# N32H7xx register map
Vendor: Nationstech Ltd.; File version: 1.0
Registers are 32-bit, read-write, reset 0x0 unless marked. A register's access mark holds for its fields unless they carry their own. Offsets are from the block's base; [hi:lo] are bit positions; {n}, {i} and the like mark numbered series; 'fields as' and 'values as' point back to an identical list.

## DMAMUX1 — DMA request multiplexer
Base 0x40046400
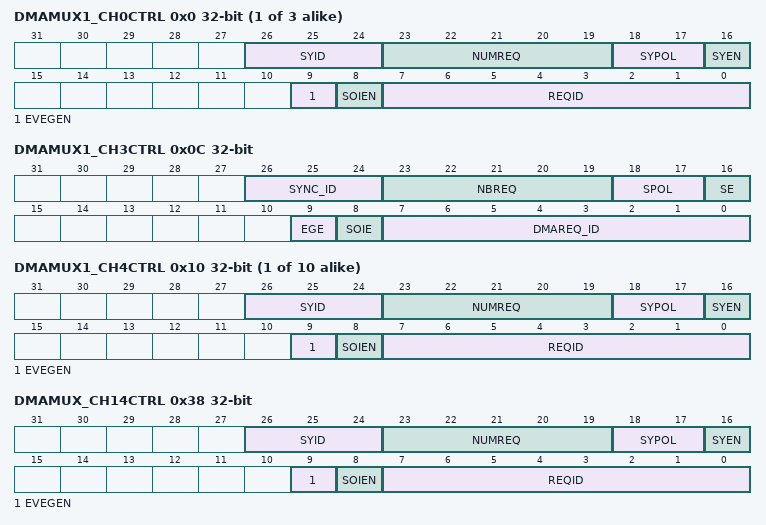
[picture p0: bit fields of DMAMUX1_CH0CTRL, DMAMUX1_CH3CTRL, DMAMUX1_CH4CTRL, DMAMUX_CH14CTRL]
{0x0+4i} DMAMUX1_CH{i}CTRL (i=0..2) — nan
  [26:24] SYID, [23:19] NUMREQ, [18:17] SYPOL, [16] SYEN, [9] EVEGEN, [8] SOIEN, [7:0] REQID
0x0C DMAMUX1_CH3CTRL — nan
  [26:24] SYNC_ID, [23:19] NBREQ, [18:17] SPOL, [16] SE, [9] EGE, [8] SOIE, [7:0] DMAREQ_ID
{0x0+4i} DMAMUX1_CH{i}CTRL (i=4..13) — nan
  fields as DMAMUX1_CH0CTRL
0x38 DMAMUX_CH14CTRL — nan
  fields as DMAMUX1_CH0CTRL
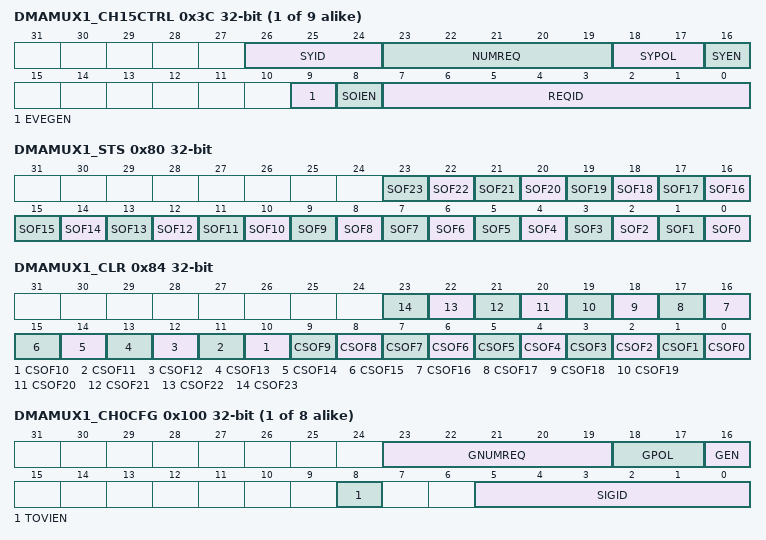
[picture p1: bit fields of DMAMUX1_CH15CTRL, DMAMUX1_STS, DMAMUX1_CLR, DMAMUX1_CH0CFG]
{0x0+4i} DMAMUX1_CH{i}CTRL (i=15..23) — nan
  fields as DMAMUX1_CH0CTRL
0x80 DMAMUX1_STS ro — nan
  [n] SOF{n} (n=0..23)
0x84 DMAMUX1_CLR — nan
  [n] CSOF{n} (n=0..23)
{0x100+4i} DMAMUX1_CH{i}CFG (i=0..7) — nan
  [23:19] GNUMREQ, [18:17] GPOL, [16] GEN, [8] TOVIEN, [5:0] SIGID
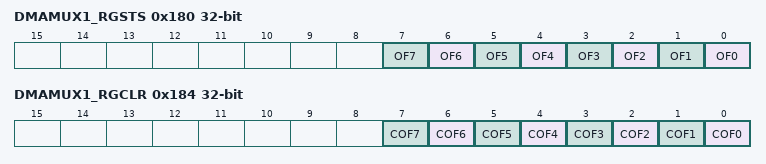
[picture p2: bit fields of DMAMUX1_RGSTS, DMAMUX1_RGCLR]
0x180 DMAMUX1_RGSTS ro — nan
  [n] OF{n} (n=0..7)
0x184 DMAMUX1_RGCLR — nan
  [n] COF{n} (n=0..7)

## DMAMUX2 — DMA request multiplexer
Base 0x51120000
Registers as DMAMUX1 (with DMAMUX1 read as DMAMUX2), without DMAMUX_CH14CTRL, DMAMUX1_CH{n}CTRL (n=16..23); these are added or differ:
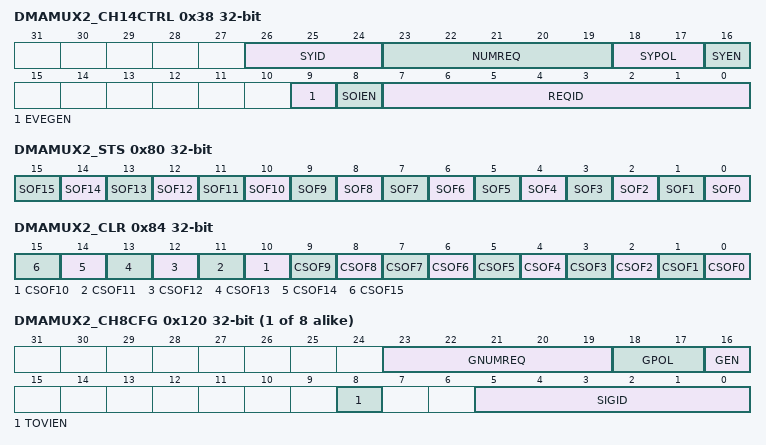
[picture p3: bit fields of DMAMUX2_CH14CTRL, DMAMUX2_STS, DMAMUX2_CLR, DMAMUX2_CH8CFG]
0x38 DMAMUX2_CH14CTRL — nan
  [26:24] SYID, [23:19] NUMREQ, [18:17] SYPOL, [16] SYEN, [9] EVEGEN, [8] SOIEN, [7:0] REQID
0x80 DMAMUX2_STS ro — nan
  [n] SOF{n} (n=0..15)
0x84 DMAMUX2_CLR — nan
  [n] CSOF{n} (n=0..15)
{0x100+4i} DMAMUX2_CH{i}CFG (i=8..15) — nan
  [23:19] GNUMREQ, [18:17] GPOL, [16] GEN, [8] TOVIEN, [5:0] SIGID
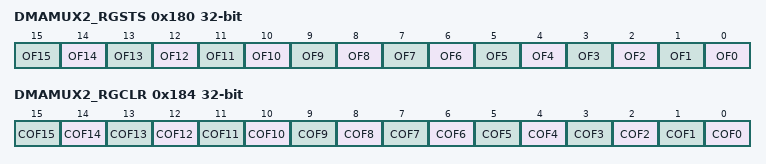
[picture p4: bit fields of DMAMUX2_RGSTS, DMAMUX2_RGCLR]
0x180 DMAMUX2_RGSTS ro — nan
  [n] OF{n} (n=0..15)
0x184 DMAMUX2_RGCLR — nan
  [n] COF{n} (n=0..15)

## DMA1 — DMA controller 1
Base 0x40046800
Same registers: DMA2 0x40046C00, DMA3 0x40047000
{0x0+0x58*i} DMA_CH{i}SA (i=0..7)
  [31:0] ADDR
{0x8+0x58*i} DMA_CH{i}DA (i=0..7)
  [31:0] ADDR
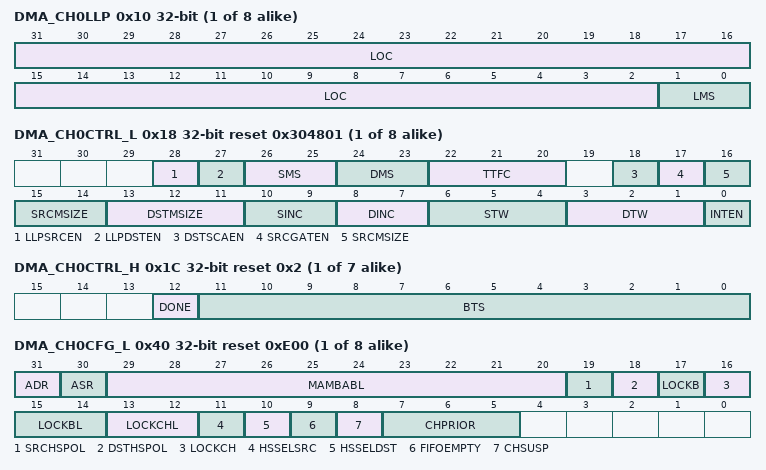
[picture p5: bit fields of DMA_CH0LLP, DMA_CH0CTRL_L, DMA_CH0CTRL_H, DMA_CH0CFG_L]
{0x10+0x58*i} DMA_CH{i}LLP (i=0..7)
  [31:2] LOC, [1:0] LMS
{0x18+0x58*i} DMA_CH{i}CTRL_L reset 0x304801 (i=0..7)
  [28] LLPSRCEN, [27] LLPDSTEN, [26:25] SMS, [24:23] DMS, [22:20] TTFC, [18] DSTSCAEN, [17] SRCGATEN, [16:14] SRCMSIZE, [13:11] DSTMSIZE, [10:9] SINC, [8:7] DINC, [6:4] STW, [3:1] DTW, [0] INTEN
{0x1C+0x58*i} DMA_CH{i}CTRL_H reset 0x2 (i=0..6)
  [12] DONE, [11:0] BTS
{0x40+0x58*i} DMA_CH{i}CFG_L reset 0xE00 (i=0..7)
  [31] ADR, [30] ASR, [29:20] MAMBABL, [19] SRCHSPOL, [18] DSTHSPOL, [17] LOCKB, [16] LOCKCH, [15:14] LOCKBL, [13:12] LOCKCHL, [11] HSSELSRC, [10] HSSELDST, [9] FIFOEMPTY, [8] CHSUSP, [7:5] CHPRIOR
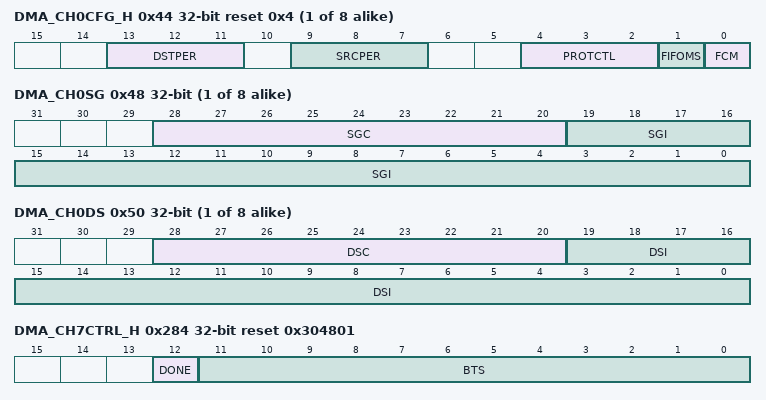
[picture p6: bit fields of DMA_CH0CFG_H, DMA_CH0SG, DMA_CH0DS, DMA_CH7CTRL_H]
{0x44+0x58*i} DMA_CH{i}CFG_H reset 0x4 (i=0..7)
  [13:11] DSTPER, [9:7] SRCPER, [4:2] PROTCTL, [1] FIFOMS, [0] FCM
{0x48+0x58*i} DMA_CH{i}SG (i=0..7)
  [28:20] SGC, [19:0] SGI
{0x50+0x58*i} DMA_CH{i}DS (i=0..7)
  [28:20] DSC, [19:0] DSI
0x284 DMA_CH7CTRL_H reset 0x304801
  [12] DONE, [11:0] BTS
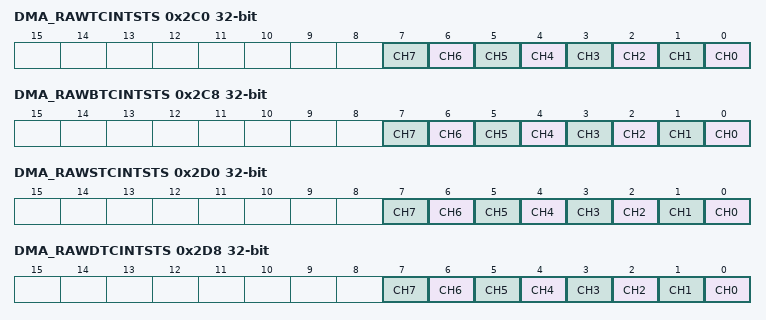
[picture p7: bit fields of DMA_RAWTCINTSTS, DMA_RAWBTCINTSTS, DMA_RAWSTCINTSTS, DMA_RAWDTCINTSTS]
0x2C0 DMA_RAWTCINTSTS
  [n] CH{n} (n=0..7)
0x2C8 DMA_RAWBTCINTSTS
  [n] CH{n} (n=0..7)
0x2D0 DMA_RAWSTCINTSTS
  [n] CH{n} (n=0..7)
0x2D8 DMA_RAWDTCINTSTS
  [n] CH{n} (n=0..7)
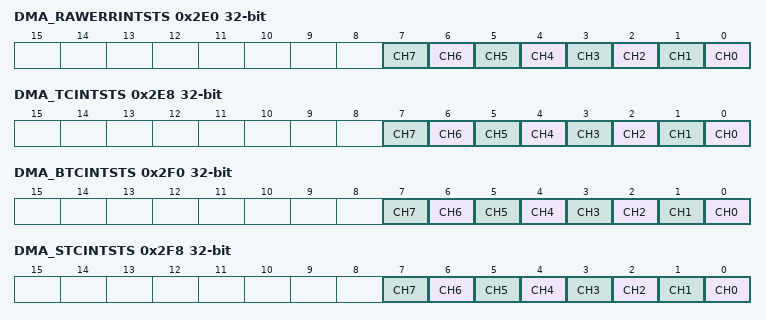
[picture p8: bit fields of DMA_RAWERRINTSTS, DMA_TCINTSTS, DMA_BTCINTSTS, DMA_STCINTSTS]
0x2E0 DMA_RAWERRINTSTS
  [n] CH{n} (n=0..7)
0x2E8 DMA_TCINTSTS
  [n] CH{n} (n=0..7)
0x2F0 DMA_BTCINTSTS
  [n] CH{n} (n=0..7)
0x2F8 DMA_STCINTSTS
  [n] CH{n} (n=0..7)
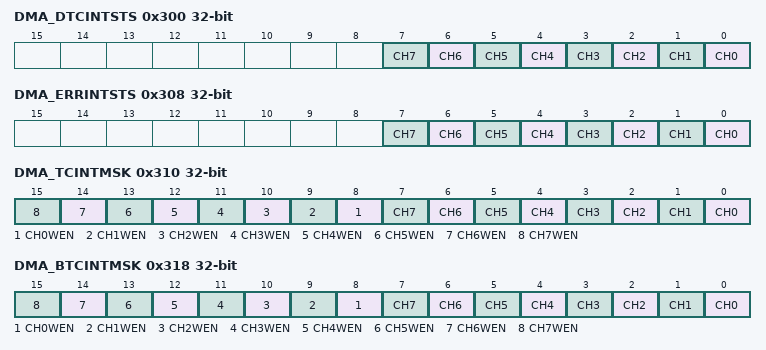
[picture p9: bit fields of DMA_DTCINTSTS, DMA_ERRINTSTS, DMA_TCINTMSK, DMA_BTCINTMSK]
0x300 DMA_DTCINTSTS
  [n] CH{n} (n=0..7)
0x308 DMA_ERRINTSTS
  [n] CH{n} (n=0..7)
0x310 DMA_TCINTMSK
  [n+8] CH{n}WEN (n=0..7), [n] CH{n} (n=0..7)
0x318 DMA_BTCINTMSK
  [n+8] CH{n}WEN (n=0..7), [n] CH{n} (n=0..7)
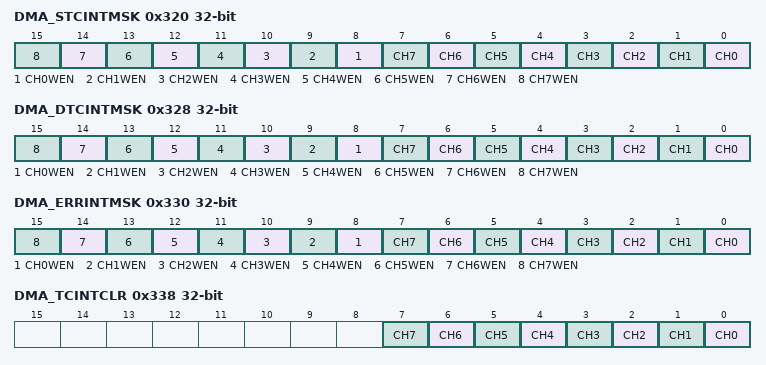
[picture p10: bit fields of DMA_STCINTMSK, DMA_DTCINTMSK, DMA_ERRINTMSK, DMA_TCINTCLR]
0x320 DMA_STCINTMSK
  [n+8] CH{n}WEN (n=0..7), [n] CH{n} (n=0..7)
0x328 DMA_DTCINTMSK
  [n+8] CH{n}WEN (n=0..7), [n] CH{n} (n=0..7)
0x330 DMA_ERRINTMSK
  [n+8] CH{n}WEN (n=0..7), [n] CH{n} (n=0..7)
0x338 DMA_TCINTCLR
  [n] CH{n} (n=0..7)
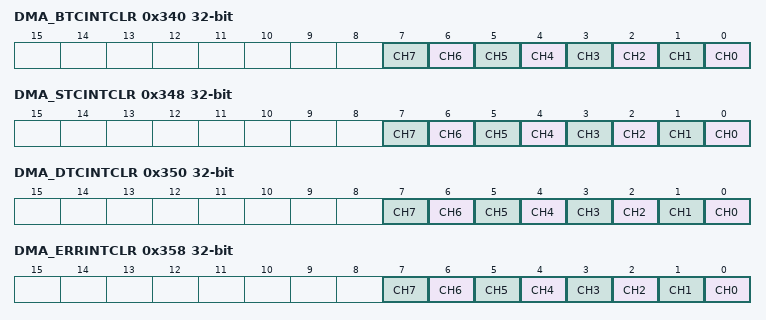
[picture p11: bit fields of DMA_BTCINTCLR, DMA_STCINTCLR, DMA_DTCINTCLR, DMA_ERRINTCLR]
0x340 DMA_BTCINTCLR
  [n] CH{n} (n=0..7)
0x348 DMA_STCINTCLR
  [n] CH{n} (n=0..7)
0x350 DMA_DTCINTCLR
  [n] CH{n} (n=0..7)
0x358 DMA_ERRINTCLR
  [n] CH{n} (n=0..7)
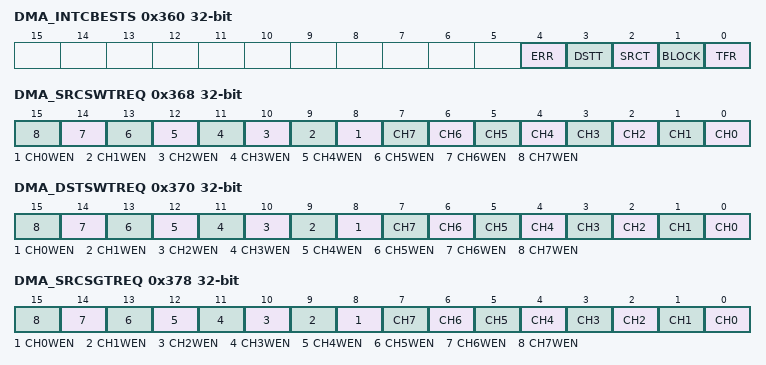
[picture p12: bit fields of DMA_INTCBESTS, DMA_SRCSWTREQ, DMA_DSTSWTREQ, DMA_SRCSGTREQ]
0x360 DMA_INTCBESTS
  [4] ERR, [3] DSTT, [2] SRCT, [1] BLOCK, [0] TFR
0x368 DMA_SRCSWTREQ
  [n+8] CH{n}WEN (n=0..7), [n] CH{n} (n=0..7)
0x370 DMA_DSTSWTREQ
  [n+8] CH{n}WEN (n=0..7), [n] CH{n} (n=0..7)
0x378 DMA_SRCSGTREQ
  [n+8] CH{n}WEN (n=0..7), [n] CH{n} (n=0..7)
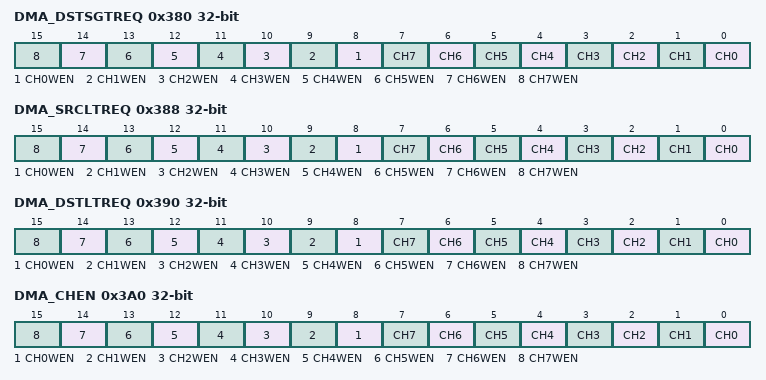
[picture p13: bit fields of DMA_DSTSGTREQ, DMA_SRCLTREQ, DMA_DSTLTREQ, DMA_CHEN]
0x380 DMA_DSTSGTREQ
  [n+8] CH{n}WEN (n=0..7), [n] CH{n} (n=0..7)
0x388 DMA_SRCLTREQ
  [n+8] CH{n}WEN (n=0..7), [n] CH{n} (n=0..7)
0x390 DMA_DSTLTREQ
  [n+8] CH{n}WEN (n=0..7), [n] CH{n} (n=0..7)
0x398 DMA_CFG
  [0] EN
0x3A0 DMA_CHEN
  [n+8] CH{n}WEN (n=0..7), [n] CH{n} (n=0..7)
0x3A8 DMA_ID
  [31:0] VALUE
0x3B0 DMA_TEST
  [0] TMS
0x3B8 DMA_LPTIMEOUT reset 0x8
  [7:0] VALUE
0x3F8 DMA_COMPID_L reset 0x44571110
  [31:0] TYPE
0x3FC DMA_COMPID_H reset 0x3232332A
  [31:0] VERSION
